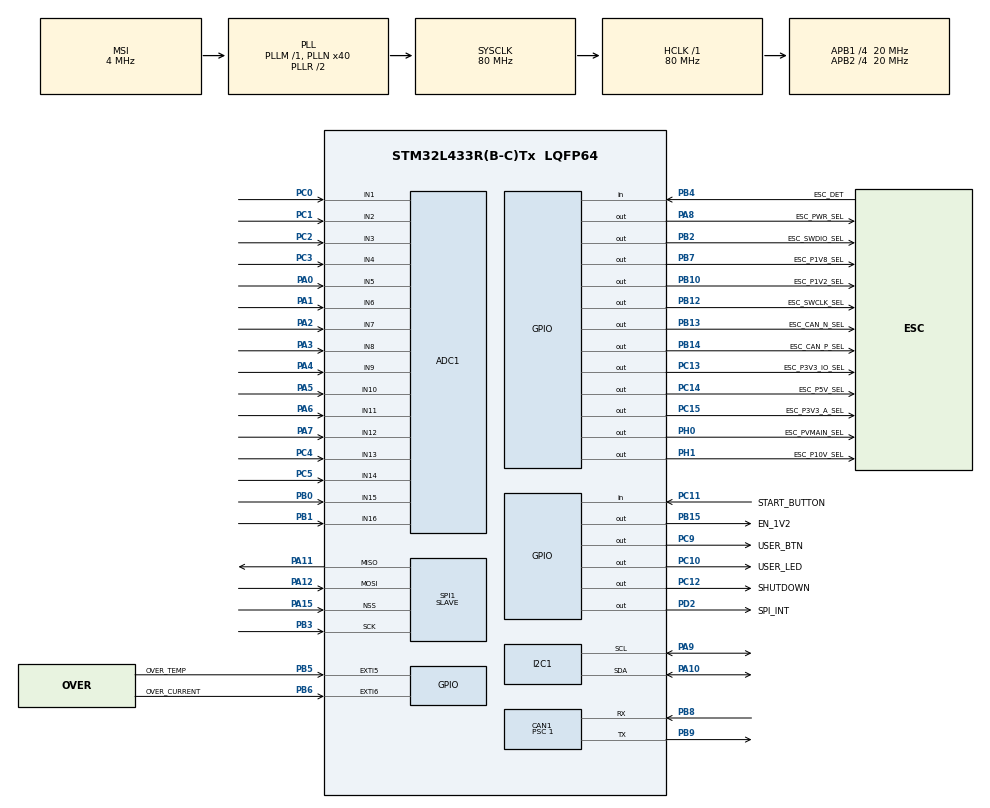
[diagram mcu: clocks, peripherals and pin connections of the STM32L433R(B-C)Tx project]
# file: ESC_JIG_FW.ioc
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ADC1.Channel-0\#ChannelRegularConversion=ADC_CHANNEL_1
ADC1.NbrOfConversionFlag=1
ADC1.OffsetNumber-0\#ChannelRegularConversion=ADC_OFFSET_NONE
ADC1.Rank-0\#ChannelRegularConversion=1
ADC1.SamplingTime-0\#ChannelRegularConversion=ADC_SAMPLETIME_640CYCLES_5
ADC1.master=1
CAN1.BS1=CAN_BS1_15TQ
CAN1.BS2=CAN_BS2_4TQ
CAN1.CalculateBaudRate=1000000
CAN1.CalculateTimeBit=1000
CAN1.CalculateTimeQuantum=50.0
CAN1.Prescaler=1
I2C1.Speed=40
I2C1.Timing=0x0060E9FF
Mcu.Family=STM32L4
Mcu.Name=STM32L433R(B-C)Tx
Mcu.Package=LQFP64
NVIC.CAN1_RX0_IRQn=true\:0\:0\:false\:false\:true\:true\:true\:true
NVIC.CAN1_RX1_IRQn=true\:0\:0\:false\:false\:true\:true\:true\:true
NVIC.CAN1_SCE_IRQn=true\:0\:0\:false\:false\:true\:true\:true\:true
NVIC.CAN1_TX_IRQn=true\:0\:0\:false\:false\:true\:true\:true\:true
NVIC.EXTI9_5_IRQn=true\:0\:0\:false\:false\:true\:true\:true\:true
NVIC.PriorityGroup=NVIC_PRIORITYGROUP_4
NVIC.SPI1_IRQn=true\:0\:0\:false\:false\:true\:true\:true\:true
PA0.Signal=ADCx_IN5
PA1.Signal=ADCx_IN6
PA10.Mode=I2C
PA10.Signal=I2C1_SDA
PA11.Mode=Full_Duplex_Slave
PA11.Signal=SPI1_MISO
PA12.Mode=Full_Duplex_Slave
PA12.Signal=SPI1_MOSI
PA13\ (JTMS-SWDIO).Mode=Serial_Wire
PA13\ (JTMS-SWDIO).Signal=SYS_JTMS-SWDIO
PA14\ (JTCK-SWCLK).Mode=Serial_Wire
PA14\ (JTCK-SWCLK).Signal=SYS_JTCK-SWCLK
PA15\ (JTDI).Mode=NSS_Signal_Hard_Input
PA15\ (JTDI).Signal=SPI1_NSS
PA2.Signal=ADCx_IN7
PA3.Signal=ADCx_IN8
PA4.Signal=ADCx_IN9
PA5.Signal=ADCx_IN10
PA6.Signal=ADCx_IN11
PA7.Signal=ADCx_IN12
PA8.GPIO_Label=ESC_PWR_SEL
PA8.Signal=GPIO_Output
PA9.Mode=I2C
PA9.Signal=I2C1_SCL
PB0.Signal=ADCx_IN15
PB1.Signal=ADCx_IN16
PB10.GPIO_Label=ESC_P1V2_SEL
PB10.Signal=GPIO_Output
PB12.GPIO_Label=ESC_SWCLK_SEL
PB12.Signal=GPIO_Output
PB13.GPIO_Label=ESC_CAN_N_SEL
PB13.Signal=GPIO_Output
PB14.GPIO_Label=ESC_CAN_P_SEL
PB14.Signal=GPIO_Output
PB15.GPIO_Label=EN_1V2
PB15.Signal=GPIO_Output
PB2.GPIO_Label=ESC_SWDIO_SEL
PB2.Signal=GPIO_Output
PB3\ (JTDO-TRACESWO).Mode=Full_Duplex_Slave
PB3\ (JTDO-TRACESWO).Signal=SPI1_SCK
PB4\ (NJTRST).GPIO_Label=ESC_DET
PB4\ (NJTRST).Signal=GPIO_Input
PB5.GPIO_Label=OVER_TEMP
PB5.Signal=GPXTI5
PB6.GPIO_Label=OVER_CURRENT
PB6.Signal=GPXTI6
PB7.GPIO_Label=ESC_P1V8_SEL
PB7.Signal=GPIO_Output
PB8.Mode=CAN_Activate
PB8.Signal=CAN1_RX
PB9.Mode=CAN_Activate
PB9.Signal=CAN1_TX
PC0.Signal=ADCx_IN1
PC1.Signal=ADCx_IN2
PC10.GPIO_Label=USER_LED
PC10.Signal=GPIO_Output
PC11.GPIO_Label=START_BUTTON
PC11.Signal=GPIO_Input
PC12.GPIO_Label=SHUTDOWN
PC12.GPIO_ModeDefaultOutputPP=GPIO_MODE_OUTPUT_OD
PC12.GPIO_PuPd=GPIO_NOPULL
PC12.GPIO_Speed=GPIO_SPEED_FREQ_MEDIUM
PC12.Signal=GPIO_Output
PC13.GPIO_Label=ESC_P3V3_IO_SEL
PC13.Signal=GPIO_Output
PC14-OSC32_IN\ (PC14).GPIO_Label=ESC_P5V_SEL
PC14-OSC32_IN\ (PC14).Signal=GPIO_Output
PC15-OSC32_OUT\ (PC15).GPIO_Label=ESC_P3V3_A_SEL
PC15-OSC32_OUT\ (PC15).Signal=GPIO_Output
PC2.Signal=ADCx_IN3
PC3.Signal=ADCx_IN4
PC4.Signal=ADCx_IN13
PC5.Signal=ADCx_IN14
PC9.GPIO_Label=USER_BTN
PC9.Signal=GPIO_Output
PD2.GPIO_Label=SPI_INT
PD2.Signal=GPIO_Output
PH0-OSC_IN\ (PH0).GPIO_Label=ESC_PVMAIN_SEL
PH0-OSC_IN\ (PH0).Signal=GPIO_Output
PH1-OSC_OUT\ (PH1).GPIO_Label=ESC_P10V_SEL
PH1-OSC_OUT\ (PH1).Signal=GPIO_Output
ProjectManager.HeapSize=0x200
ProjectManager.StackSize=0x400
ProjectManager.TargetToolchain=STM32CubeIDE
RCC.ADCFreq_Value=32000000
RCC.AHBFreq_Value=80000000
RCC.APB1CLKDivider=RCC_HCLK_DIV4
RCC.APB1Freq_Value=20000000
RCC.APB1TimFreq_Value=40000000
RCC.APB2CLKDivider=RCC_HCLK_DIV4
RCC.APB2Freq_Value=20000000
RCC.APB2TimFreq_Value=40000000
RCC.CortexFreq_Value=80000000
RCC.HCLKFreq_Value=80000000
RCC.HSE_VALUE=8000000
RCC.HSI48_VALUE=48000000
RCC.HSI_VALUE=16000000
RCC.LSE_VALUE=32768
RCC.MSI_VALUE=4000000
RCC.PLLN=40
RCC.PLLSAI1N=16
RCC.SYSCLKFreq_VALUE=80000000
RCC.SYSCLKSource=RCC_SYSCLKSOURCE_PLLCLK
RCC.USBFreq_Value=32000000
RCC.VCOOutputFreq_Value=160000000
SH.ADCx_IN1.0=ADC1_IN1,IN1-Single-Ended
SH.ADCx_IN10.0=ADC1_IN10,IN10-Single-Ended
SH.ADCx_IN11.0=ADC1_IN11,IN11-Single-Ended
SH.ADCx_IN12.0=ADC1_IN12,IN12-Single-Ended
SH.ADCx_IN13.0=ADC1_IN13,IN13-Single-Ended
SH.ADCx_IN14.0=ADC1_IN14,IN14-Single-Ended
SH.ADCx_IN15.0=ADC1_IN15,IN15-Single-Ended
SH.ADCx_IN16.0=ADC1_IN16,IN16-Single-Ended
SH.ADCx_IN2.0=ADC1_IN2,IN2-Single-Ended
SH.ADCx_IN3.0=ADC1_IN3,IN3-Single-Ended
SH.ADCx_IN4.0=ADC1_IN4,IN4-Single-Ended
SH.ADCx_IN5.0=ADC1_IN5,IN5-Single-Ended
SH.ADCx_IN6.0=ADC1_IN6,IN6-Single-Ended
SH.ADCx_IN7.0=ADC1_IN7,IN7-Single-Ended
SH.ADCx_IN8.0=ADC1_IN8,IN8-Single-Ended
SH.ADCx_IN9.0=ADC1_IN9,IN9-Single-Ended
SPI1.DataSize=SPI_DATASIZE_8BIT
SPI1.Direction=SPI_DIRECTION_2LINES
SPI1.Mode=SPI_MODE_SLAVE
SPI1.VirtualNSS=VM_NSSHARD
SPI1.VirtualType=VM_SLAVE
board=custom

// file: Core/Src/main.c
/* USER CODE BEGIN Header */
/**
  ******************************************************************************
  * @file           : main.c
  * @brief          : Main program body
  ******************************************************************************
  * @attention
  *
  * Copyright (c) 2025 STMicroelectronics.
  * All rights reserved.
  *
  * This software is licensed under terms that can be found in the LICENSE file
  * in the root directory of this software component.
  * If no LICENSE file comes with this software, it is provided AS-IS.
  *
  ******************************************************************************
  */
/* USER CODE END Header */
#include "main.h"

/* USER CODE BEGIN Includes */
#include "app.h"
/* USER CODE END Includes */

ADC_HandleTypeDef hadc1;

CAN_HandleTypeDef hcan1;

I2C_HandleTypeDef hi2c1;

SPI_HandleTypeDef hspi1;

void SystemClock_Config(void);
static void MX_GPIO_Init(void);
static void MX_ADC1_Init(void);
static void MX_CAN1_Init(void);
static void MX_SPI1_Init(void);
static void MX_I2C1_Init(void);

int main(void)
{

  /* MCU Configuration--------------------------------------------------------*/

  /* Reset of all peripherals, Initializes the Flash interface and the Systick. */
  HAL_Init();

  /* Configure the system clock */
  SystemClock_Config();

  /* Initialize all configured peripherals */
  MX_GPIO_Init();
  MX_ADC1_Init();
  MX_CAN1_Init();
  MX_SPI1_Init();
  MX_I2C1_Init();
  /* USER CODE BEGIN 2 */
  app_init(&hadc1, &hcan1, &hspi1, &hi2c1);
  /* USER CODE END 2 */

  /* Infinite loop */
  while (1)
  {

  }
}

void SystemClock_Config(void)
{
  RCC_OscInitTypeDef RCC_OscInitStruct = {0};
  RCC_ClkInitTypeDef RCC_ClkInitStruct = {0};

  /** Configure the main internal regulator output voltage
  */
  if (HAL_PWREx_ControlVoltageScaling(PWR_REGULATOR_VOLTAGE_SCALE1) != HAL_OK)
  {
    Error_Handler();
  }

  /** Initializes the RCC Oscillators according to the specified parameters
  * in the RCC_OscInitTypeDef structure.
  */
  RCC_OscInitStruct.OscillatorType = RCC_OSCILLATORTYPE_MSI;
  RCC_OscInitStruct.MSIState = RCC_MSI_ON;
  RCC_OscInitStruct.MSICalibrationValue = 0;
  RCC_OscInitStruct.MSIClockRange = RCC_MSIRANGE_6;
  RCC_OscInitStruct.PLL.PLLState = RCC_PLL_ON;
  RCC_OscInitStruct.PLL.PLLSource = RCC_PLLSOURCE_MSI;
  RCC_OscInitStruct.PLL.PLLM = 1;
  RCC_OscInitStruct.PLL.PLLN = 40;
  RCC_OscInitStruct.PLL.PLLP = RCC_PLLP_DIV7;
  RCC_OscInitStruct.PLL.PLLQ = RCC_PLLQ_DIV2;
  RCC_OscInitStruct.PLL.PLLR = RCC_PLLR_DIV2;
  if (HAL_RCC_OscConfig(&RCC_OscInitStruct) != HAL_OK)
  {
    Error_Handler();
  }

  /** Initializes the CPU, AHB and APB buses clocks
  */
  RCC_ClkInitStruct.ClockType = RCC_CLOCKTYPE_HCLK|RCC_CLOCKTYPE_SYSCLK
                              |RCC_CLOCKTYPE_PCLK1|RCC_CLOCKTYPE_PCLK2;
  RCC_ClkInitStruct.SYSCLKSource = RCC_SYSCLKSOURCE_PLLCLK;
  RCC_ClkInitStruct.AHBCLKDivider = RCC_SYSCLK_DIV1;
  RCC_ClkInitStruct.APB1CLKDivider = RCC_HCLK_DIV4;
  RCC_ClkInitStruct.APB2CLKDivider = RCC_HCLK_DIV4;

  if (HAL_RCC_ClockConfig(&RCC_ClkInitStruct, FLASH_LATENCY_4) != HAL_OK)
  {
    Error_Handler();
  }
}

static void MX_ADC1_Init(void)
{

  ADC_ChannelConfTypeDef sConfig = {0};

  /** Common config
  */
  hadc1.Instance = ADC1;
  hadc1.Init.ClockPrescaler = ADC_CLOCK_ASYNC_DIV1;
  hadc1.Init.Resolution = ADC_RESOLUTION_12B;
  hadc1.Init.DataAlign = ADC_DATAALIGN_RIGHT;
  hadc1.Init.ScanConvMode = ADC_SCAN_DISABLE;
  hadc1.Init.EOCSelection = ADC_EOC_SINGLE_CONV;
  hadc1.Init.LowPowerAutoWait = DISABLE;
  hadc1.Init.ContinuousConvMode = DISABLE;
  hadc1.Init.NbrOfConversion = 1;
  hadc1.Init.DiscontinuousConvMode = DISABLE;
  hadc1.Init.ExternalTrigConv = ADC_SOFTWARE_START;
  hadc1.Init.ExternalTrigConvEdge = ADC_EXTERNALTRIGCONVEDGE_NONE;
  hadc1.Init.DMAContinuousRequests = DISABLE;
  hadc1.Init.Overrun = ADC_OVR_DATA_PRESERVED;
  hadc1.Init.OversamplingMode = DISABLE;
  if (HAL_ADC_Init(&hadc1) != HAL_OK)
  {
    Error_Handler();
  }

  /** Configure Regular Channel
  */
  sConfig.Channel = ADC_CHANNEL_1;
  sConfig.Rank = ADC_REGULAR_RANK_1;
  sConfig.SamplingTime = ADC_SAMPLETIME_640CYCLES_5;
  sConfig.SingleDiff = ADC_SINGLE_ENDED;
  sConfig.OffsetNumber = ADC_OFFSET_NONE;
  sConfig.Offset = 0;
  if (HAL_ADC_ConfigChannel(&hadc1, &sConfig) != HAL_OK)
  {
    Error_Handler();
  }

}

static void MX_CAN1_Init(void)
{

  hcan1.Instance = CAN1;
  hcan1.Init.Prescaler = 1;
  hcan1.Init.Mode = CAN_MODE_NORMAL;
  hcan1.Init.SyncJumpWidth = CAN_SJW_1TQ;
  hcan1.Init.TimeSeg1 = CAN_BS1_15TQ;
  hcan1.Init.TimeSeg2 = CAN_BS2_4TQ;
  hcan1.Init.TimeTriggeredMode = DISABLE;
  hcan1.Init.AutoBusOff = DISABLE;
  hcan1.Init.AutoWakeUp = DISABLE;
  hcan1.Init.AutoRetransmission = DISABLE;
  hcan1.Init.ReceiveFifoLocked = DISABLE;
  hcan1.Init.TransmitFifoPriority = DISABLE;
  if (HAL_CAN_Init(&hcan1) != HAL_OK)
  {
    Error_Handler();
  }

}

static void MX_I2C1_Init(void)
{

  hi2c1.Instance = I2C1;
  hi2c1.Init.Timing = 0x0060E9FF;
  hi2c1.Init.OwnAddress1 = 0;
  hi2c1.Init.AddressingMode = I2C_ADDRESSINGMODE_7BIT;
  hi2c1.Init.DualAddressMode = I2C_DUALADDRESS_DISABLE;
  hi2c1.Init.OwnAddress2 = 0;
  hi2c1.Init.OwnAddress2Masks = I2C_OA2_NOMASK;
  hi2c1.Init.GeneralCallMode = I2C_GENERALCALL_DISABLE;
  hi2c1.Init.NoStretchMode = I2C_NOSTRETCH_DISABLE;
  if (HAL_I2C_Init(&hi2c1) != HAL_OK)
  {
    Error_Handler();
  }

  /** Configure Analogue filter
  */
  if (HAL_I2CEx_ConfigAnalogFilter(&hi2c1, I2C_ANALOGFILTER_ENABLE) != HAL_OK)
  {
    Error_Handler();
  }

  /** Configure Digital filter
  */
  if (HAL_I2CEx_ConfigDigitalFilter(&hi2c1, 0) != HAL_OK)
  {
    Error_Handler();
  }

}

static void MX_SPI1_Init(void)
{

  /* SPI1 parameter configuration*/
  hspi1.Instance = SPI1;
  hspi1.Init.Mode = SPI_MODE_SLAVE;
  hspi1.Init.Direction = SPI_DIRECTION_2LINES;
  hspi1.Init.DataSize = SPI_DATASIZE_8BIT;
  hspi1.Init.CLKPolarity = SPI_POLARITY_LOW;
  hspi1.Init.CLKPhase = SPI_PHASE_1EDGE;
  hspi1.Init.NSS = SPI_NSS_HARD_INPUT;
  hspi1.Init.FirstBit = SPI_FIRSTBIT_MSB;
  hspi1.Init.TIMode = SPI_TIMODE_DISABLE;
  hspi1.Init.CRCCalculation = SPI_CRCCALCULATION_DISABLE;
  hspi1.Init.CRCPolynomial = 7;
  hspi1.Init.CRCLength = SPI_CRC_LENGTH_DATASIZE;
  hspi1.Init.NSSPMode = SPI_NSS_PULSE_DISABLE;
  if (HAL_SPI_Init(&hspi1) != HAL_OK)
  {
    Error_Handler();
  }

}

static void MX_GPIO_Init(void)
{
  GPIO_InitTypeDef GPIO_InitStruct = {0};

  /* GPIO Ports Clock Enable */
  __HAL_RCC_GPIOC_CLK_ENABLE();
  __HAL_RCC_GPIOH_CLK_ENABLE();
  __HAL_RCC_GPIOA_CLK_ENABLE();
  __HAL_RCC_GPIOB_CLK_ENABLE();
  __HAL_RCC_GPIOD_CLK_ENABLE();

  /*Configure GPIO pin Output Level */
  HAL_GPIO_WritePin(GPIOC, ESC_P3V3_IO_SEL_Pin|ESC_P5V_SEL_Pin|ESC_P3V3_A_SEL_Pin|USER_BTN_Pin
                          |USER_LED_Pin|SHUTDOWN_Pin, GPIO_PIN_RESET);

  /*Configure GPIO pin Output Level */
  HAL_GPIO_WritePin(GPIOH, ESC_PVMAIN_SEL_Pin|ESC_P10V_SEL_Pin, GPIO_PIN_RESET);

  /*Configure GPIO pin Output Level */
  HAL_GPIO_WritePin(GPIOB, ESC_SWDIO_SEL_Pin|ESC_P1V2_SEL_Pin|ESC_SWCLK_SEL_Pin|ESC_CAN_N_SEL_Pin
                          |ESC_CAN_P_SEL_Pin|EN_1V2_Pin|ESC_P1V8_SEL_Pin, GPIO_PIN_RESET);

  /*Configure GPIO pin Output Level */
  HAL_GPIO_WritePin(ESC_PWR_SEL_GPIO_Port, ESC_PWR_SEL_Pin, GPIO_PIN_RESET);

  /*Configure GPIO pin Output Level */
  HAL_GPIO_WritePin(SPI_INT_GPIO_Port, SPI_INT_Pin, GPIO_PIN_RESET);

  /*Configure GPIO pins : ESC_P3V3_IO_SEL_Pin ESC_P5V_SEL_Pin ESC_P3V3_A_SEL_Pin USER_BTN_Pin
                           USER_LED_Pin */
  GPIO_InitStruct.Pin = ESC_P3V3_IO_SEL_Pin|ESC_P5V_SEL_Pin|ESC_P3V3_A_SEL_Pin|USER_BTN_Pin
                          |USER_LED_Pin;
  GPIO_InitStruct.Mode = GPIO_MODE_OUTPUT_PP;
  GPIO_InitStruct.Pull = GPIO_NOPULL;
  GPIO_InitStruct.Speed = GPIO_SPEED_FREQ_LOW;
  HAL_GPIO_Init(GPIOC, &GPIO_InitStruct);

  /*Configure GPIO pins : ESC_PVMAIN_SEL_Pin ESC_P10V_SEL_Pin */
  GPIO_InitStruct.Pin = ESC_PVMAIN_SEL_Pin|ESC_P10V_SEL_Pin;
  GPIO_InitStruct.Mode = GPIO_MODE_OUTPUT_PP;
  GPIO_InitStruct.Pull = GPIO_NOPULL;
  GPIO_InitStruct.Speed = GPIO_SPEED_FREQ_LOW;
  HAL_GPIO_Init(GPIOH, &GPIO_InitStruct);

  /*Configure GPIO pins : ESC_SWDIO_SEL_Pin ESC_P1V2_SEL_Pin ESC_SWCLK_SEL_Pin ESC_CAN_N_SEL_Pin
                           ESC_CAN_P_SEL_Pin EN_1V2_Pin ESC_P1V8_SEL_Pin */
  GPIO_InitStruct.Pin = ESC_SWDIO_SEL_Pin|ESC_P1V2_SEL_Pin|ESC_SWCLK_SEL_Pin|ESC_CAN_N_SEL_Pin
                          |ESC_CAN_P_SEL_Pin|EN_1V2_Pin|ESC_P1V8_SEL_Pin;
  GPIO_InitStruct.Mode = GPIO_MODE_OUTPUT_PP;
  GPIO_InitStruct.Pull = GPIO_NOPULL;
  GPIO_InitStruct.Speed = GPIO_SPEED_FREQ_LOW;
  HAL_GPIO_Init(GPIOB, &GPIO_InitStruct);

  /*Configure GPIO pin : ESC_PWR_SEL_Pin */
  GPIO_InitStruct.Pin = ESC_PWR_SEL_Pin;
  GPIO_InitStruct.Mode = GPIO_MODE_OUTPUT_PP;
  GPIO_InitStruct.Pull = GPIO_NOPULL;
  GPIO_InitStruct.Speed = GPIO_SPEED_FREQ_LOW;
  HAL_GPIO_Init(ESC_PWR_SEL_GPIO_Port, &GPIO_InitStruct);

  /*Configure GPIO pin : START_BUTTON_Pin */
  GPIO_InitStruct.Pin = START_BUTTON_Pin;
  GPIO_InitStruct.Mode = GPIO_MODE_INPUT;
  GPIO_InitStruct.Pull = GPIO_NOPULL;
  HAL_GPIO_Init(START_BUTTON_GPIO_Port, &GPIO_InitStruct);

  /*Configure GPIO pin : SHUTDOWN_Pin */
  GPIO_InitStruct.Pin = SHUTDOWN_Pin;
  GPIO_InitStruct.Mode = GPIO_MODE_OUTPUT_OD;
  GPIO_InitStruct.Pull = GPIO_NOPULL;
  GPIO_InitStruct.Speed = GPIO_SPEED_FREQ_MEDIUM;
  HAL_GPIO_Init(SHUTDOWN_GPIO_Port, &GPIO_InitStruct);

  /*Configure GPIO pin : SPI_INT_Pin */
  GPIO_InitStruct.Pin = SPI_INT_Pin;
  GPIO_InitStruct.Mode = GPIO_MODE_OUTPUT_PP;
  GPIO_InitStruct.Pull = GPIO_NOPULL;
  GPIO_InitStruct.Speed = GPIO_SPEED_FREQ_LOW;
  HAL_GPIO_Init(SPI_INT_GPIO_Port, &GPIO_InitStruct);

  /*Configure GPIO pin : ESC_DET_Pin */
  GPIO_InitStruct.Pin = ESC_DET_Pin;
  GPIO_InitStruct.Mode = GPIO_MODE_INPUT;
  GPIO_InitStruct.Pull = GPIO_NOPULL;
  HAL_GPIO_Init(ESC_DET_GPIO_Port, &GPIO_InitStruct);

  /*Configure GPIO pins : OVER_TEMP_Pin OVER_CURRENT_Pin */
  GPIO_InitStruct.Pin = OVER_TEMP_Pin|OVER_CURRENT_Pin;
  GPIO_InitStruct.Mode = GPIO_MODE_IT_RISING;
  GPIO_InitStruct.Pull = GPIO_NOPULL;
  HAL_GPIO_Init(GPIOB, &GPIO_InitStruct);

  /* EXTI interrupt init*/
  HAL_NVIC_SetPriority(EXTI9_5_IRQn, 0, 0);
  HAL_NVIC_EnableIRQ(EXTI9_5_IRQn);

}

void Error_Handler(void)
{
  /* USER CODE BEGIN Error_Handler_Debug */
  /* User can add his own implementation to report the HAL error return state */
  while (1)
  {
	  HAL_GPIO_TogglePin(USER_LED_GPIO_Port, USER_LED_Pin);
	  HAL_Delay(500);
  }
  /* USER CODE END Error_Handler_Debug */
}
